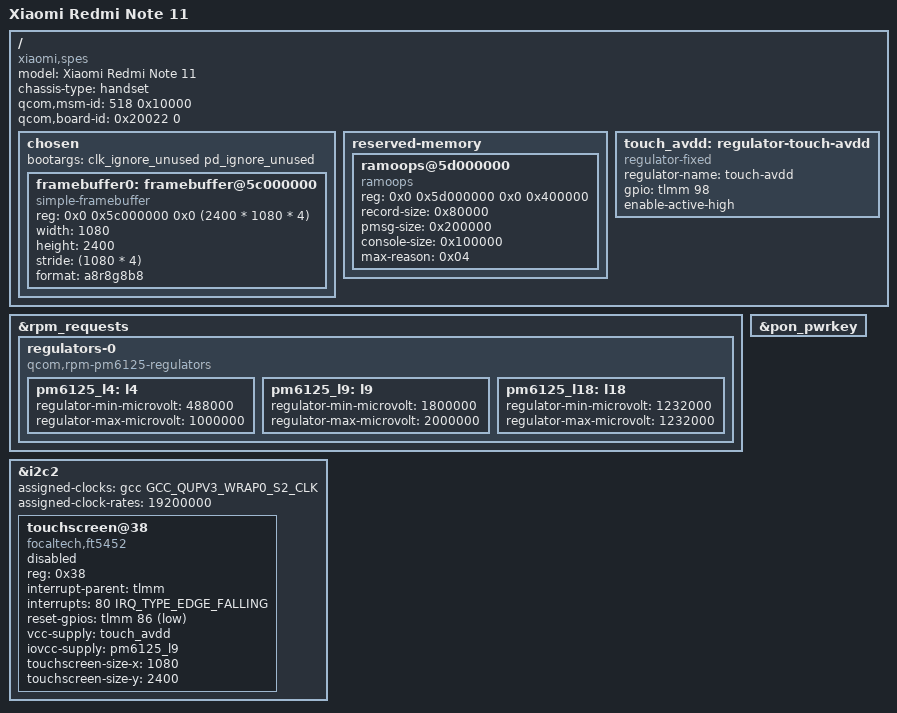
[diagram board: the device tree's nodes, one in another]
// SPDX-License-Identifier: BSD-3-Clause
/*
 * Xiaomi Redmi Note 11 (spes), Qualcomm SM6225 / Khaje.
 *
 * Derived from the early Mainline bring-up DTS in
 * external-mirrors/sm6225-mainline-linux, branch sm6225/v6.19-rc8,
 * commit 467185042fc7a8e2da4589767dd0d7b8ddc422e8
 * (original DTS blob 4a2b84c19250adc18c79b67df38d7d6bb332e6fb).
 *
 * This is a compile candidate, not a boot-tested board DTS. MSM/board IDs,
 * framebuffer, ramoops, PMIC and touchscreen wiring must be reconciled with
 * the exact handset firmware/live FDT before any boot attempt.
 *
 * Copyright (c) 2026, Rayan Marzouk <rayanmarzouk743@gmail.com>
 */

/dts-v1/;
#include <dt-bindings/gpio/gpio.h>
#include <dt-bindings/interrupt-controller/irq.h>
#include "sm6225.dtsi"
#include "pm6125.dtsi"

/ {
	model = "Xiaomi Redmi Note 11";
	compatible = "xiaomi,spes", "qcom,sm6225";
	chassis-type = "handset";

	/* Candidate XBL identifiers from the referenced spes DTS. */
	qcom,msm-id = <518 0x10000>;
	qcom,board-id = <0x20022 0>;

	chosen {
		#address-cells = <2>;
		#size-cells = <2>;
		ranges;

		/* Temporary bring-up flags; remove after clock/power drivers work. */
		bootargs = "clk_ignore_unused pd_ignore_unused";

		/*
		 * Candidate bootloader framebuffer from same-model external
		 * hardware evidence. Verify address/format against live FDT.
		 */
		framebuffer0: framebuffer@5c000000 {
			compatible = "simple-framebuffer";
			reg = <0x0 0x5c000000 0x0 (2400 * 1080 * 4)>;
			width = <1080>;
			height = <2400>;
			stride = <(1080 * 4)>;
			format = "a8r8g8b8";
		};
	};

	reserved-memory {
		#address-cells = <2>;
		#size-cells = <2>;
		ranges;

		/*
		 * Candidate ramoops range follows the SM6225 SoC DTSI splash
		 * and dfps reservations. Verify against the live FDT first.
		 * The pinned pmos SM6225 source is expected to reserve the modem
		 * carveout at 0x4ab00000/0x06900000 and WLAN MSA at
		 * 0x51900000/0x00100000 (the early mirror DTSI did not). Verify
		 * both in the pinned source and live Spes FDT; do not duplicate them.
		 */
		ramoops@5d000000 {
			compatible = "ramoops";
			reg = <0x0 0x5d000000 0x0 0x400000>;
			record-size = <0x80000>;
			pmsg-size = <0x200000>;
			console-size = <0x100000>;
			max-reason = <0x04>;
		};
	};

	/*
	 * Stock Spes touch AVDD is enabled by TLMM GPIO98. Represent it as a
	 * fixed regulator so the upstream edt-ft5x06 driver can sequence it.
	 * Rail voltage is intentionally unspecified: the public Spes sources
	 * identify the enable GPIO but not its voltage.
	 */
	touch_avdd: regulator-touch-avdd {
		compatible = "regulator-fixed";
		regulator-name = "touch-avdd";
		gpio = <&tlmm 98 GPIO_ACTIVE_HIGH>;
		enable-active-high;
	};
};

/*
 * The SM6225 CAMSS node in the pinned SoC DTSI consumes PM6125 L4 and L18.
 * Values below are provisional electrical ranges cross-checked against the
 * upstream SM6115/PM6125 board DTS. They are compile-time declarations only:
 * verify the exact Spes PMIC rail programming from its live DTB/vendor data
 * before enabling camera or attempting a physical boot.
 */
&rpm_requests {
	regulators-0 {
		compatible = "qcom,rpm-pm6125-regulators";

		pm6125_l4: l4 {
			regulator-min-microvolt = <488000>;
			regulator-max-microvolt = <1000000>;
		};

		pm6125_l9: l9 {
			regulator-min-microvolt = <1800000>;
			regulator-max-microvolt = <2000000>;
		};

		pm6125_l18: l18 {
			regulator-min-microvolt = <1232000>;
			regulator-max-microvolt = <1232000>;
		};
	};
};

/* PM6125 power key. */
&pon_pwrkey {
	status = "okay";
};

/*
 * QUPv3 SE2 is the stock Spes touchscreen I2C bus. The SM6225 Mainline
 * reference pins this GENI I2C source clock to XO (19.2 MHz). GPIO80 is
 * supported by the Tapas reference and independent Spes hardware report;
 * one downstream vendor interrupts property says GPIO89 instead.
 */
&i2c2 {
	assigned-clocks = <&gcc GCC_QUPV3_WRAP0_S2_CLK>;
	assigned-clock-rates = <19200000>;
	status = "okay";

	/*
	 * Upstream FocalTech FT5452 candidate. Kept disabled until the live
	 * Spes DTB resolves the IRQ discrepancy and confirms power sequencing.
	 */
	touchscreen@38 {
		compatible = "focaltech,ft5452";
		reg = <0x38>;
		interrupt-parent = <&tlmm>;
		interrupts = <80 IRQ_TYPE_EDGE_FALLING>;
		reset-gpios = <&tlmm 86 GPIO_ACTIVE_LOW>;
		vcc-supply = <&touch_avdd>;
		iovcc-supply = <&pm6125_l9>;
		touchscreen-size-x = <1080>;
		touchscreen-size-y = <2400>;
		status = "disabled";
	};
};
